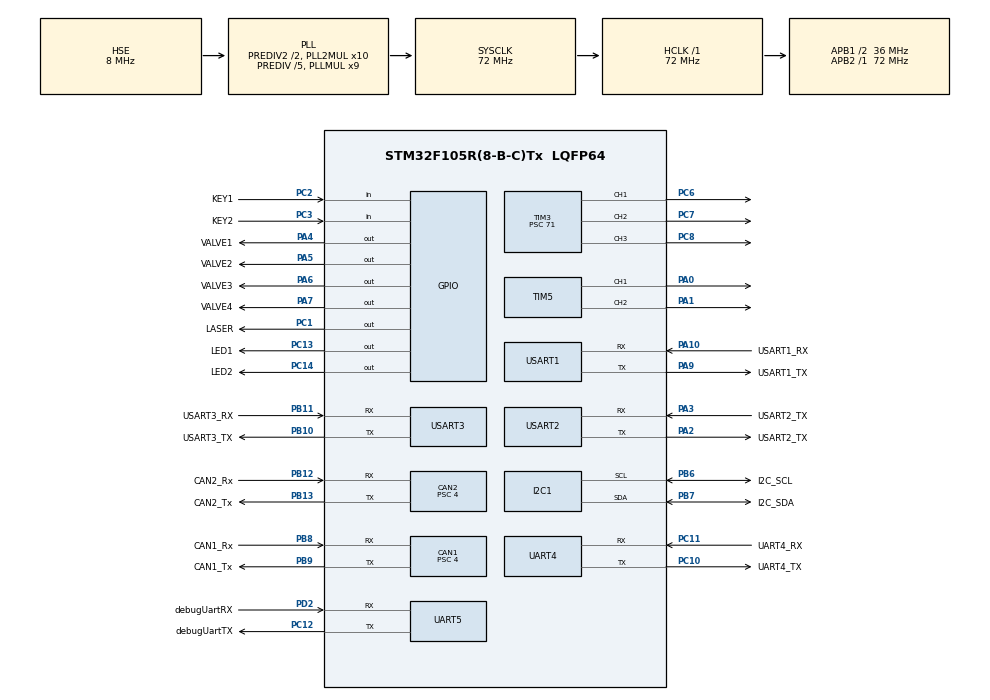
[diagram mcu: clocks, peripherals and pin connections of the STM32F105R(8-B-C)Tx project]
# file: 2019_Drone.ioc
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CAN1.ABOM=ENABLE
CAN1.AWUM=ENABLE
CAN1.BS1=CAN_BS1_5TQ
CAN1.BS2=CAN_BS2_3TQ
CAN1.CalculateTimeBit=1000
CAN1.CalculateTimeQuantum=111.11111111111111
CAN1.NART=ENABLE
CAN1.Prescaler=4
CAN1.RFLM=ENABLE
CAN1.TTCM=ENABLE
CAN1.TXFP=ENABLE
CAN2.ABOM=ENABLE
CAN2.AWUM=ENABLE
CAN2.BS1=CAN_BS1_5TQ
CAN2.BS2=CAN_BS2_3TQ
CAN2.CalculateTimeBit=1000
CAN2.CalculateTimeQuantum=111.11111111111111
CAN2.NART=ENABLE
CAN2.Prescaler=4
CAN2.TXFP=ENABLE
Dma.MEMTOMEM.0.Direction=DMA_MEMORY_TO_MEMORY
Dma.MEMTOMEM.0.Instance=DMA1_Channel1
Dma.MEMTOMEM.0.MemDataAlignment=DMA_MDATAALIGN_BYTE
Dma.MEMTOMEM.0.MemInc=DMA_MINC_ENABLE
Dma.MEMTOMEM.0.Mode=DMA_NORMAL
Dma.MEMTOMEM.0.PeriphDataAlignment=DMA_PDATAALIGN_BYTE
Dma.MEMTOMEM.0.PeriphInc=DMA_PINC_ENABLE
Dma.MEMTOMEM.0.Priority=DMA_PRIORITY_LOW
Dma.Request0=MEMTOMEM
Dma.Request1=USART2_RX
Dma.Request2=USART2_TX
Dma.Request3=USART3_RX
Dma.Request4=USART3_TX
Dma.Request5=USART1_RX
Dma.Request6=USART1_TX
Dma.Request7=UART4_RX
Dma.UART4_RX.7.Direction=DMA_PERIPH_TO_MEMORY
Dma.UART4_RX.7.Instance=DMA2_Channel3
Dma.UART4_RX.7.MemDataAlignment=DMA_MDATAALIGN_BYTE
Dma.UART4_RX.7.MemInc=DMA_MINC_ENABLE
Dma.UART4_RX.7.Mode=DMA_NORMAL
Dma.UART4_RX.7.PeriphDataAlignment=DMA_PDATAALIGN_BYTE
Dma.UART4_RX.7.PeriphInc=DMA_PINC_DISABLE
Dma.UART4_RX.7.Priority=DMA_PRIORITY_LOW
Dma.USART1_RX.5.Direction=DMA_PERIPH_TO_MEMORY
Dma.USART1_RX.5.Instance=DMA1_Channel5
Dma.USART1_RX.5.MemDataAlignment=DMA_MDATAALIGN_BYTE
Dma.USART1_RX.5.MemInc=DMA_MINC_ENABLE
Dma.USART1_RX.5.Mode=DMA_NORMAL
Dma.USART1_RX.5.PeriphDataAlignment=DMA_PDATAALIGN_BYTE
Dma.USART1_RX.5.PeriphInc=DMA_PINC_DISABLE
Dma.USART1_RX.5.Priority=DMA_PRIORITY_LOW
Dma.USART1_TX.6.Direction=DMA_MEMORY_TO_PERIPH
Dma.USART1_TX.6.Instance=DMA1_Channel4
Dma.USART1_TX.6.MemDataAlignment=DMA_MDATAALIGN_BYTE
Dma.USART1_TX.6.MemInc=DMA_MINC_ENABLE
Dma.USART1_TX.6.Mode=DMA_NORMAL
Dma.USART1_TX.6.PeriphDataAlignment=DMA_PDATAALIGN_BYTE
Dma.USART1_TX.6.PeriphInc=DMA_PINC_DISABLE
Dma.USART1_TX.6.Priority=DMA_PRIORITY_LOW
Dma.USART2_RX.1.Direction=DMA_PERIPH_TO_MEMORY
Dma.USART2_RX.1.Instance=DMA1_Channel6
Dma.USART2_RX.1.MemDataAlignment=DMA_MDATAALIGN_BYTE
Dma.USART2_RX.1.MemInc=DMA_MINC_ENABLE
Dma.USART2_RX.1.Mode=DMA_NORMAL
Dma.USART2_RX.1.PeriphDataAlignment=DMA_PDATAALIGN_BYTE
Dma.USART2_RX.1.PeriphInc=DMA_PINC_DISABLE
Dma.USART2_RX.1.Priority=DMA_PRIORITY_LOW
Dma.USART2_TX.2.Direction=DMA_MEMORY_TO_PERIPH
Dma.USART2_TX.2.Instance=DMA1_Channel7
Dma.USART2_TX.2.MemDataAlignment=DMA_MDATAALIGN_BYTE
Dma.USART2_TX.2.MemInc=DMA_MINC_ENABLE
Dma.USART2_TX.2.Mode=DMA_NORMAL
Dma.USART2_TX.2.PeriphDataAlignment=DMA_PDATAALIGN_BYTE
Dma.USART2_TX.2.PeriphInc=DMA_PINC_DISABLE
Dma.USART2_TX.2.Priority=DMA_PRIORITY_LOW
Dma.USART3_RX.3.Direction=DMA_PERIPH_TO_MEMORY
Dma.USART3_RX.3.Instance=DMA1_Channel3
Dma.USART3_RX.3.MemDataAlignment=DMA_MDATAALIGN_BYTE
Dma.USART3_RX.3.MemInc=DMA_MINC_ENABLE
Dma.USART3_RX.3.Mode=DMA_NORMAL
Dma.USART3_RX.3.PeriphDataAlignment=DMA_PDATAALIGN_BYTE
Dma.USART3_RX.3.PeriphInc=DMA_PINC_DISABLE
Dma.USART3_RX.3.Priority=DMA_PRIORITY_LOW
Dma.USART3_TX.4.Direction=DMA_MEMORY_TO_PERIPH
Dma.USART3_TX.4.Instance=DMA1_Channel2
Dma.USART3_TX.4.MemDataAlignment=DMA_MDATAALIGN_BYTE
Dma.USART3_TX.4.MemInc=DMA_MINC_ENABLE
Dma.USART3_TX.4.Mode=DMA_NORMAL
Dma.USART3_TX.4.PeriphDataAlignment=DMA_PDATAALIGN_BYTE
Dma.USART3_TX.4.PeriphInc=DMA_PINC_DISABLE
Dma.USART3_TX.4.Priority=DMA_PRIORITY_LOW
FREERTOS.Tasks01=defaultTask,0,128,StartDefaultTask,Default,NULL
FREERTOS.configUSE_PREEMPTION=1
FREERTOS.configUSE_TIMERS=1
Mcu.Family=STM32F1
Mcu.Name=STM32F105R(8-B-C)Tx
Mcu.Package=LQFP64
NVIC.CAN1_RX0_IRQn=true\:5\:0\:false\:false\:true\:true\:true
NVIC.CAN2_RX0_IRQn=true\:5\:0\:false\:false\:true\:true\:true
NVIC.DMA1_Channel2_IRQn=true\:5\:0\:false\:false\:true\:true\:false
NVIC.DMA1_Channel3_IRQn=true\:5\:0\:false\:false\:true\:true\:false
NVIC.DMA1_Channel4_IRQn=true\:5\:0\:false\:false\:true\:true\:false
NVIC.DMA1_Channel5_IRQn=true\:5\:0\:false\:false\:true\:true\:false
NVIC.DMA1_Channel6_IRQn=true\:5\:0\:false\:false\:true\:true\:false
NVIC.DMA1_Channel7_IRQn=true\:5\:0\:false\:false\:true\:true\:false
NVIC.DMA2_Channel3_IRQn=true\:5\:0\:false\:false\:true\:true\:false
NVIC.PriorityGroup=NVIC_PRIORITYGROUP_4
NVIC.TIM1_UP_IRQn=true\:5\:0\:false\:false\:true\:true\:true
NVIC.TIM3_IRQn=true\:5\:0\:false\:false\:true\:true\:true
NVIC.TIM4_IRQn=true\:5\:0\:false\:false\:true\:true\:true
NVIC.UART4_IRQn=true\:5\:0\:false\:false\:true\:true\:true
NVIC.UART5_IRQn=true\:5\:0\:false\:false\:true\:true\:true
NVIC.USART1_IRQn=true\:5\:0\:false\:false\:true\:true\:true
NVIC.USART2_IRQn=true\:5\:0\:false\:false\:true\:true\:true
NVIC.USART3_IRQn=true\:5\:0\:false\:false\:true\:true\:true
PA0-WKUP.Signal=S_TIM5_CH1
PA1.Signal=S_TIM5_CH2
PA10.GPIO_Label=USART1_RX
PA10.Mode=Multiprocessor_communication
PA10.Signal=USART1_RX
PA13.Mode=Serial_Wire
PA13.Signal=SYS_JTMS-SWDIO
PA14.Mode=Serial_Wire
PA14.Signal=SYS_JTCK-SWCLK
PA2.GPIO_Label=USART2_TX
PA2.Mode=Multiprocessor_communication
PA2.Signal=USART2_TX
PA3.GPIO_Label=USART2_TX
PA3.Mode=Multiprocessor_communication
PA3.Signal=USART2_RX
PA4.GPIO_Label=VALVE1
PA4.Signal=GPIO_Output
PA5.GPIO_Label=VALVE2
PA5.Signal=GPIO_Output
PA6.GPIO_Label=VALVE3
PA6.Signal=GPIO_Output
PA7.GPIO_Label=VALVE4
PA7.Signal=GPIO_Output
PA9.GPIO_Label=USART1_TX
PA9.Mode=Multiprocessor_communication
PA9.Signal=USART1_TX
PB10.GPIO_Label=USART3_TX
PB10.Mode=Multiprocessor_communication
PB10.Signal=USART3_TX
PB11.GPIO_Label=USART3_RX
PB11.Mode=Multiprocessor_communication
PB11.Signal=USART3_RX
PB12.GPIO_Label=CAN2_Rx
PB12.Mode=Slave
PB12.Signal=CAN2_RX
PB13.GPIO_Label=CAN2_Tx
PB13.Mode=Slave
PB13.Signal=CAN2_TX
PB6.GPIO_Label=I2C_SCL
PB6.Mode=I2C
PB6.Signal=I2C1_SCL
PB7.GPIO_Label=I2C_SDA
PB7.Mode=I2C
PB7.Signal=I2C1_SDA
PB8.GPIO_Label=CAN1_Rx
PB8.Mode=Master
PB8.Signal=CAN1_RX
PB9.GPIO_Label=CAN1_Tx
PB9.Mode=Master
PB9.Signal=CAN1_TX
PC1.GPIO_Label=LASER
PC1.Signal=GPIO_Output
PC10.GPIO_Label=UART4_TX
PC10.Mode=Multiprocessor_communication
PC10.Signal=UART4_TX
PC11.GPIO_Label=UART4_RX
PC11.Mode=Multiprocessor_communication
PC11.Signal=UART4_RX
PC12.GPIO_Label=debugUartTX
PC12.Mode=Multiprocessor_communication
PC12.Signal=UART5_TX
PC13-TAMPER-RTC.GPIO_Label=LED1
PC13-TAMPER-RTC.Signal=GPIO_Output
PC14-OSC32_IN.GPIO_Label=LED2
PC14-OSC32_IN.Signal=GPIO_Output
PC2.GPIO_Label=KEY1
PC2.Signal=GPIO_Input
PC3.GPIO_Label=KEY2
PC3.Signal=GPIO_Input
PC6.Signal=S_TIM3_CH1
PC7.Signal=S_TIM3_CH2
PC8.Signal=S_TIM3_CH3
PD0-OSC_IN.Mode=HSE-External-Oscillator
PD0-OSC_IN.Signal=RCC_OSC_IN
PD1-OSC_OUT.Mode=HSE-External-Oscillator
PD1-OSC_OUT.Signal=RCC_OSC_OUT
PD2.GPIO_Label=debugUartRX
PD2.Mode=Multiprocessor_communication
PD2.Signal=UART5_RX
ProjectManager.HeapSize=0x200
ProjectManager.StackSize=0x400
ProjectManager.TargetToolchain=MDK-ARM V5
RCC.AHBFreq_Value=72000000
RCC.APB1CLKDivider=RCC_HCLK_DIV2
RCC.APB1Freq_Value=36000000
RCC.APB1TimFreq_Value=72000000
RCC.APB2Freq_Value=72000000
RCC.APB2TimFreq_Value=72000000
RCC.HCLKFreq_Value=72000000
RCC.HSEDivPLL=RCC_HSE_PREDIV_DIV5
RCC.PLL2Mul=RCC_PLL2_MUL10
RCC.PLLMUL=RCC_PLL_MUL9
RCC.PLLSourceVirtual=RCC_PLLSOURCE_HSE
RCC.Prediv1Source=RCC_PREDIV1_SOURCE_PLL2
RCC.Prediv2=RCC_HSE_PREDIV2_DIV2
RCC.SYSCLKFreq_VALUE=72000000
RCC.SYSCLKSource=RCC_SYSCLKSOURCE_PLLCLK
RCC.USBFreq_Value=48000000
SH.S_TIM3_CH1.0=TIM3_CH1,PWM Generation1 CH1
SH.S_TIM3_CH2.0=TIM3_CH2,PWM Generation2 CH2
SH.S_TIM3_CH3.0=TIM3_CH3,PWM Generation3 CH3
SH.S_TIM5_CH1.0=TIM5_CH1,PWM Generation1 CH1
SH.S_TIM5_CH2.0=TIM5_CH2,PWM Generation2 CH2
TIM1.Period=999
TIM1.Prescaler=71
TIM3.Channel-PWM\ Generation1\ CH1=TIM_CHANNEL_1
TIM3.Channel-PWM\ Generation2\ CH2=TIM_CHANNEL_2
TIM3.Channel-PWM\ Generation3\ CH3=TIM_CHANNEL_3
TIM3.Prescaler=71
TIM3.Pulse-PWM\ Generation1\ CH1=12
TIM3.Pulse-PWM\ Generation2\ CH2=12
TIM3.Pulse-PWM\ Generation3\ CH3=12
TIM4.Prescaler=71
TIM5.Channel-PWM\ Generation1\ CH1=TIM_CHANNEL_1
TIM5.Channel-PWM\ Generation2\ CH2=TIM_CHANNEL_2
UART4.VirtualMode=Asynchronous
UART5.VirtualMode=Asynchronous
USART1.VirtualMode=VM_ASYNC
USART2.VirtualMode=VM_ASYNC
USART3.VirtualMode=VM_ASYNC
VP_FREERTOS_VS_ENABLE.Mode=Enabled
VP_TIM1_VS_ClockSourceINT.Mode=Internal
VP_TIM4_VS_ClockSourceINT.Mode=Internal
board=custom

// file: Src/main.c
/* USER CODE BEGIN Header */
/**
  ******************************************************************************
  * @file           : main.c
  * @brief          : Main program body
  ******************************************************************************
  ** This notice applies to any and all portions of this file
  * that are not between comment pairs USER CODE BEGIN and
  * USER CODE END. Other portions of this file, whether
  * inserted by the user or by software development tools
  * are owned by their respective copyright owners.
  *
  * COPYRIGHT(c) 2019 STMicroelectronics
  *
  * Redistribution and use in source and binary forms, with or without modification,
  * are permitted provided that the following conditions are met:
  *   1. Redistributions of source code must retain the above copyright notice,
  *      this list of conditions and the following disclaimer.
  *   2. Redistributions in binary form must reproduce the above copyright notice,
  *      this list of conditions and the following disclaimer in the documentation
  *      and/or other materials provided with the distribution.
  *   3. Neither the name of STMicroelectronics nor the names of its contributors
  *      may be used to endorse or promote products derived from this software
  *      without specific prior written permission.
  *
  * THIS SOFTWARE IS PROVIDED BY THE COPYRIGHT HOLDERS AND CONTRIBUTORS "AS IS"
  * AND ANY EXPRESS OR IMPLIED WARRANTIES, INCLUDING, BUT NOT LIMITED TO, THE
  * IMPLIED WARRANTIES OF MERCHANTABILITY AND FITNESS FOR A PARTICULAR PURPOSE ARE
  * DISCLAIMED. IN NO EVENT SHALL THE COPYRIGHT HOLDER OR CONTRIBUTORS BE LIABLE
  * FOR ANY DIRECT, INDIRECT, INCIDENTAL, SPECIAL, EXEMPLARY, OR CONSEQUENTIAL
  * DAMAGES (INCLUDING, BUT NOT LIMITED TO, PROCUREMENT OF SUBSTITUTE GOODS OR
  * SERVICES; LOSS OF USE, DATA, OR PROFITS; OR BUSINESS INTERRUPTION) HOWEVER
  * CAUSED AND ON ANY THEORY OF LIABILITY, WHETHER IN CONTRACT, STRICT LIABILITY,
  * OR TORT (INCLUDING NEGLIGENCE OR OTHERWISE) ARISING IN ANY WAY OUT OF THE USE
  * OF THIS SOFTWARE, EVEN IF ADVISED OF THE POSSIBILITY OF SUCH DAMAGE.
  *
  ******************************************************************************
  */
/* USER CODE END Header */

#include "main.h"
#include "cmsis_os.h"
#include "can.h"
#include "dma.h"
#include "i2c.h"
#include "tim.h"
#include "usart.h"
#include "gpio.h"

/* USER CODE BEGIN Includes */
#include "board.h"
#include "device.h"
/* USER CODE END Includes */

/* USER CODE BEGIN PV */
/* Private variables ---------------------------------------------------------*/

/* USER CODE END PV */

void SystemClock_Config(void);
void MX_FREERTOS_Init(void);
/* USER CODE BEGIN PFP */
/* Private function prototypes -----------------------------------------------*/

/* USER CODE END PFP */

/* USER CODE BEGIN 0 */
uint8_t tempData[30];
uint8_t receiveBegin = 0;
float value = 0;
uint32_t aSRC_Buffer[3];

/* USER CODE END 0 */

int main(void)
{

  /* MCU Configuration--------------------------------------------------------*/

  /* Reset of all peripherals, Initializes the Flash interface and the Systick. */
  HAL_Init();

  /* Configure the system clock */
  SystemClock_Config();

  /* Initialize all configured peripherals */
  MX_GPIO_Init();
  MX_DMA_Init();
  MX_CAN1_Init();
  MX_CAN2_Init();
  MX_USART3_UART_Init();
  MX_I2C1_Init();
  MX_UART4_Init();
  MX_USART1_UART_Init();
  MX_USART2_UART_Init();
  MX_TIM3_Init();
  MX_TIM4_Init();
  MX_TIM1_Init();
  MX_UART5_Init();
  MX_TIM5_Init();
  /* USER CODE BEGIN 2 */
  CanFilterInit(&hcan1);
  CanFilterInit(&hcan2);
  /* USER CODE END 2 */

  /* Call init function for freertos objects (in freertos.c) */
  MX_FREERTOS_Init();

  /* Start scheduler */
  osKernelStart();

  /* We should never get here as control is now taken by the scheduler */

  /* Infinite loop */
  /* USER CODE BEGIN WHILE */

  while(1)
  {
		setDshotValue(100);

	  HAL_Delay(40);
    /* USER CODE END WHILE */

  }
}

void SystemClock_Config(void)
{
  RCC_OscInitTypeDef RCC_OscInitStruct = {0};
  RCC_ClkInitTypeDef RCC_ClkInitStruct = {0};

  /**Initializes the CPU, AHB and APB busses clocks
  */
  RCC_OscInitStruct.OscillatorType = RCC_OSCILLATORTYPE_HSE;
  RCC_OscInitStruct.HSEState = RCC_HSE_ON;
  RCC_OscInitStruct.HSEPredivValue = RCC_HSE_PREDIV_DIV5;
  RCC_OscInitStruct.HSIState = RCC_HSI_ON;
  RCC_OscInitStruct.Prediv1Source = RCC_PREDIV1_SOURCE_PLL2;
  RCC_OscInitStruct.PLL.PLLState = RCC_PLL_ON;
  RCC_OscInitStruct.PLL.PLLSource = RCC_PLLSOURCE_HSE;
  RCC_OscInitStruct.PLL.PLLMUL = RCC_PLL_MUL9;
  RCC_OscInitStruct.PLL2.PLL2State = RCC_PLL2_ON;
  RCC_OscInitStruct.PLL2.PLL2MUL = RCC_PLL2_MUL10;
  RCC_OscInitStruct.PLL2.HSEPrediv2Value = RCC_HSE_PREDIV2_DIV2;
  if (HAL_RCC_OscConfig(&RCC_OscInitStruct) != HAL_OK)
  {
    Error_Handler();
  }
  /**Initializes the CPU, AHB and APB busses clocks
  */
  RCC_ClkInitStruct.ClockType = RCC_CLOCKTYPE_HCLK|RCC_CLOCKTYPE_SYSCLK
                              |RCC_CLOCKTYPE_PCLK1|RCC_CLOCKTYPE_PCLK2;
  RCC_ClkInitStruct.SYSCLKSource = RCC_SYSCLKSOURCE_PLLCLK;
  RCC_ClkInitStruct.AHBCLKDivider = RCC_SYSCLK_DIV1;
  RCC_ClkInitStruct.APB1CLKDivider = RCC_HCLK_DIV2;
  RCC_ClkInitStruct.APB2CLKDivider = RCC_HCLK_DIV1;

  if (HAL_RCC_ClockConfig(&RCC_ClkInitStruct, FLASH_LATENCY_2) != HAL_OK)
  {
    Error_Handler();
  }
  /**Configure the Systick interrupt time
  */
  __HAL_RCC_PLLI2S_ENABLE();
}

/* USER CODE BEGIN 4 */
/**
  * @brief This function handles System tick timer.
  */
//int sys_cnt = 0;
//void SysTick_Handler(void)
//{
//  if(sys_cnt >5)
//  {
////	  CanTransmit_1234( &hcan2, 0x1ff);
//	  HAL_IncTick();
//	  sys_cnt = 0;
//  }
//  sys_cnt++;
//
//}
/* USER CODE END 4 */

void Error_Handler(void)
{
  while(1)
  {
  }
}

/************************ (C) COPYRIGHT STMicroelectronics *****END OF FILE****/
